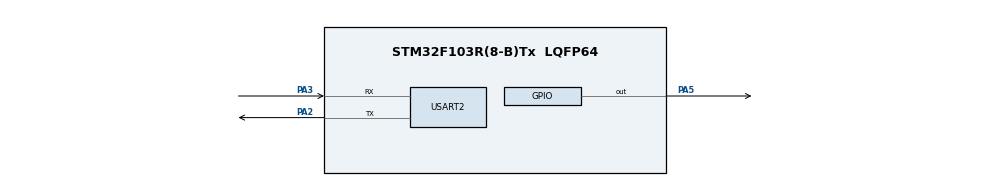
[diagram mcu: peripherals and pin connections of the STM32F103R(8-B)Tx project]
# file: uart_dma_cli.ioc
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Dma.Request0=USART2_RX
Dma.USART2_RX.0.Direction=DMA_PERIPH_TO_MEMORY
Dma.USART2_RX.0.Instance=DMA1_Channel6
Dma.USART2_RX.0.MemDataAlignment=DMA_MDATAALIGN_BYTE
Dma.USART2_RX.0.MemInc=DMA_MINC_ENABLE
Dma.USART2_RX.0.Mode=DMA_CIRCULAR
Dma.USART2_RX.0.PeriphDataAlignment=DMA_PDATAALIGN_BYTE
Dma.USART2_RX.0.PeriphInc=DMA_PINC_DISABLE
Dma.USART2_RX.0.Priority=DMA_PRIORITY_LOW
Mcu.Family=STM32F1
Mcu.Name=STM32F103R(8-B)Tx
Mcu.Package=LQFP64
NVIC.DMA1_Channel6_IRQn=true\:0\:0\:false\:false\:true\:false\:true\:true
NVIC.PriorityGroup=NVIC_PRIORITYGROUP_4
NVIC.USART2_IRQn=true\:0\:0\:false\:false\:true\:true\:true\:true
PA2.Mode=Asynchronous
PA2.Signal=USART2_TX
PA3.Mode=Asynchronous
PA3.Signal=USART2_RX
PA5.Signal=GPIO_Output
ProjectManager.HeapSize=0x200
ProjectManager.StackSize=0x400
ProjectManager.TargetToolchain=STM32CubeIDE
RCC.APB1Freq_Value=8000000
RCC.APB2Freq_Value=8000000
USART2.VirtualMode=VM_ASYNC
VP_SYS_VS_ND.Mode=No_Debug
board=custom

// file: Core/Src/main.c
/* USER CODE BEGIN Header */
/**
  ******************************************************************************
  * @file           : main.c
  * @brief          : Main program body
  ******************************************************************************
  * @attention
  *
  * Copyright (c) 2026 STMicroelectronics.
  * All rights reserved.
  *
  * This software is licensed under terms that can be found in the LICENSE file
  * in the root directory of this software component.
  * If no LICENSE file comes with this software, it is provided AS-IS.
  *
  ******************************************************************************
  */
/* USER CODE END Header */
#include "main.h"

/* USER CODE BEGIN Includes */
#include "cli.h"
/* USER CODE END Includes */

UART_HandleTypeDef huart2;
DMA_HandleTypeDef hdma_usart2_rx;

/* USER CODE BEGIN PV */
#define RX_BUF_SIZE 128

uint8_t dma_rx_buf[RX_BUF_SIZE];
uint16_t old_pos = 0;
/* USER CODE END PV */

void SystemClock_Config(void);
static void MX_GPIO_Init(void);
static void MX_DMA_Init(void);
static void MX_USART2_UART_Init(void);

int main(void)
{

  /* MCU Configuration--------------------------------------------------------*/

  /* Reset of all peripherals, Initializes the Flash interface and the Systick. */
  HAL_Init();

  /* Configure the system clock */
  SystemClock_Config();

  /* Initialize all configured peripherals */
  MX_GPIO_Init();
  MX_DMA_Init();
  MX_USART2_UART_Init();
  /* USER CODE BEGIN 2 */
  /* Place application initialization code here. */
  CLI_Init(&huart2);
  HAL_UART_Receive_DMA(&huart2, dma_rx_buf, RX_BUF_SIZE);
  /* USER CODE END 2 */

  /* Infinite loop */
  while (1)
  {
	  uint16_t new_pos = RX_BUF_SIZE - __HAL_DMA_GET_COUNTER(huart2.hdmarx);

	  if (new_pos != old_pos)
	  {
		  if (new_pos > old_pos)
		  {
		      for (uint16_t i = old_pos; i < new_pos; i++)
		      {
		          CLI_InputChar(dma_rx_buf[i]);
		      }
		  }
		  else
		  {
		      for (uint16_t i = old_pos; i < RX_BUF_SIZE; i++)
		      {
		          CLI_InputChar(dma_rx_buf[i]);
		      }

		      for (uint16_t i = 0; i < new_pos; i++)
		      {
		          CLI_InputChar(dma_rx_buf[i]);
		      }
		  }

		  old_pos = new_pos;
	  }
  }
    /* USER CODE BEGIN 3 */
    /* Place application loop code here. */
  /* USER CODE END 3 */
}

void SystemClock_Config(void)
{
  RCC_OscInitTypeDef RCC_OscInitStruct = {0};
  RCC_ClkInitTypeDef RCC_ClkInitStruct = {0};

  /** Initializes the RCC Oscillators according to the specified parameters
  * in the RCC_OscInitTypeDef structure.
  */
  RCC_OscInitStruct.OscillatorType = RCC_OSCILLATORTYPE_HSI;
  RCC_OscInitStruct.HSIState = RCC_HSI_ON;
  RCC_OscInitStruct.HSICalibrationValue = RCC_HSICALIBRATION_DEFAULT;
  RCC_OscInitStruct.PLL.PLLState = RCC_PLL_NONE;
  if (HAL_RCC_OscConfig(&RCC_OscInitStruct) != HAL_OK)
  {
    Error_Handler();
  }

  /** Initializes the CPU, AHB and APB buses clocks
  */
  RCC_ClkInitStruct.ClockType = RCC_CLOCKTYPE_HCLK|RCC_CLOCKTYPE_SYSCLK
                              |RCC_CLOCKTYPE_PCLK1|RCC_CLOCKTYPE_PCLK2;
  RCC_ClkInitStruct.SYSCLKSource = RCC_SYSCLKSOURCE_HSI;
  RCC_ClkInitStruct.AHBCLKDivider = RCC_SYSCLK_DIV1;
  RCC_ClkInitStruct.APB1CLKDivider = RCC_HCLK_DIV1;
  RCC_ClkInitStruct.APB2CLKDivider = RCC_HCLK_DIV1;

  if (HAL_RCC_ClockConfig(&RCC_ClkInitStruct, FLASH_LATENCY_0) != HAL_OK)
  {
    Error_Handler();
  }
}

static void MX_USART2_UART_Init(void)
{

  huart2.Instance = USART2;
  huart2.Init.BaudRate = 115200;
  huart2.Init.WordLength = UART_WORDLENGTH_8B;
  huart2.Init.StopBits = UART_STOPBITS_1;
  huart2.Init.Parity = UART_PARITY_NONE;
  huart2.Init.Mode = UART_MODE_TX_RX;
  huart2.Init.HwFlowCtl = UART_HWCONTROL_NONE;
  huart2.Init.OverSampling = UART_OVERSAMPLING_16;
  if (HAL_UART_Init(&huart2) != HAL_OK)
  {
    Error_Handler();
  }

}

static void MX_DMA_Init(void)
{

  /* DMA controller clock enable */
  __HAL_RCC_DMA1_CLK_ENABLE();

  /* DMA interrupt init */
  /* DMA1_Channel6_IRQn interrupt configuration */
  HAL_NVIC_SetPriority(DMA1_Channel6_IRQn, 0, 0);
  HAL_NVIC_EnableIRQ(DMA1_Channel6_IRQn);

}

static void MX_GPIO_Init(void)
{
  GPIO_InitTypeDef GPIO_InitStruct = {0};

  /* GPIO Ports Clock Enable */
  __HAL_RCC_GPIOA_CLK_ENABLE();

  /*Configure GPIO pin Output Level */
  HAL_GPIO_WritePin(GPIOA, GPIO_PIN_5, GPIO_PIN_RESET);

  /*Configure GPIO pin : PA5 */
  GPIO_InitStruct.Pin = GPIO_PIN_5;
  GPIO_InitStruct.Mode = GPIO_MODE_OUTPUT_PP;
  GPIO_InitStruct.Pull = GPIO_NOPULL;
  GPIO_InitStruct.Speed = GPIO_SPEED_FREQ_LOW;
  HAL_GPIO_Init(GPIOA, &GPIO_InitStruct);

}

void Error_Handler(void)
{
  __disable_irq();
  while (1)
  {
  }
}
